# psoc6_04 register map
Vendor: Cypress Semiconductor; Series: PSoC6_04; File version: 1.0
CPU: CM4 r0p1, little endian, MPU, FPU, VTOR, 3 interrupt priority bits
Registers are 32-bit, read-write, reset 0x0 unless marked. A register's access mark holds for its fields unless they carry their own. Offsets are from the block's base; [hi:lo] are bit positions; {n}, {i} and the like mark numbered series; <NAME> marks a mode.

## SAR0 — SAR ADC with Sequencer
Base 0x409B0000
Same registers: SAR1 0x409C0000
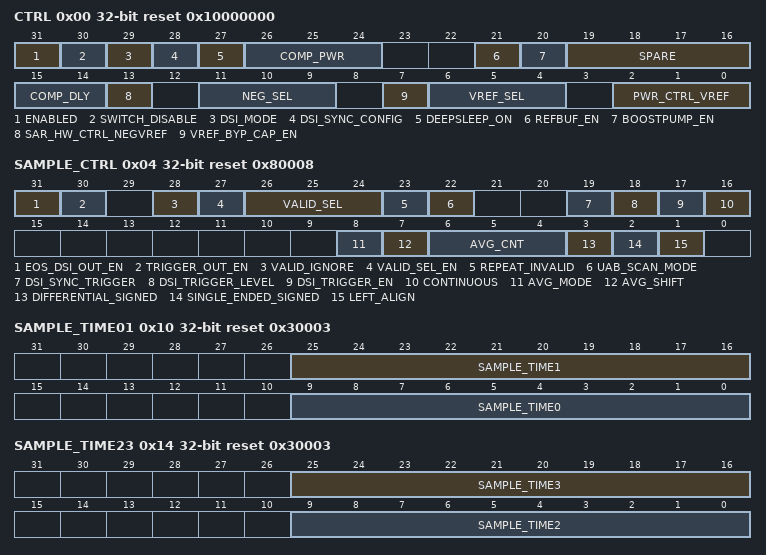
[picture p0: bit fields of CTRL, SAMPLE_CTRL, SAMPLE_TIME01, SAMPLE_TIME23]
0x00 CTRL reset 0x10000000 — Analog control register.
  [31] ENABLED — - 0: SAR IP disabled (put analog in power down and stop clocks), also can clear FW_TRIGGER and INJ_START_EN (if not tailgating) on write. - 1: SAR IP enabled.
  [30] SWITCH_DISABLE — Disable SAR sequencer from enabling routing switches (note DSI and firmware can always close switches independent of this control) - 0: Normal mode, SAR sequencer changes switches according to pin address in channel configurations - 1: Switches disabled, SAR sequencer does not enable any switches, it is the responsibility of the firmware or UDBs (through DSI) to set the switches to route the signal to be converted through the SARMUX
  [29] DSI_MODE — SAR sequencer takes configuration from DSI signals (note this also has the same effect as SWITCH_DISABLE==1) - 0: Normal mode, SAR sequencer operates according to CHAN_EN enables and CHAN_CONFIG channel configurations - 1: CHAN_EN, INJ_START_EN and channel configurations in CHAN_CONFIG and INJ_CHAN_CONFIG are ignored
  [28] DSI_SYNC_CONFIG — - 0: bypass clock domain synchronization of the DSI config signals. - 1: synchronize the DSI config signals to peripheral clock domain.
  [27] DEEPSLEEP_ON — - 0: SARMUX IP disabled off during DeepSleep power mode - 1: SARMUX IP remains enabled during DeepSleep power mode (if ENABLED=1)
  [26:24] COMP_PWR — Comparator power mode. (Sample rate TBD)
    0=P100 (Power = 100 percent, Use this for SAR Clock Frequency greater than 18MHz); 1=P80 (N/A); 2=P60 (Power = 60 percent, Use this for SAR Clock Frequency greater than 1.8MHz up to 18MHz.); 3=P50 (N/A); 4=P40 (N/A); 5=P30 (N/A); 6=P20 (Power = 20 percent, Use this for SAR Clock Frequency less than or equal to 1.8MHz); 7=P10 (N/A)
  [21] REFBUF_EN — For normal ADC operation this bit must be set, for all reference choices - internal, external or vdda based reference. Setting this bit is critical to proper function of switches inside SARREF block.
  [20] BOOSTPUMP_EN — deprecated
  [19:16] SPARE — Spare controls, not yet designated, for late changes done with an ECO
  [15:14] COMP_DLY — Set the comparator latch delay in accordance with SAR conversion rate
    0=D2P5 (2.5ns delay, use this for 2.5Msps); 1=D4 (4.0ns delay, use this for 2.0Msps); 2=D10 (10ns delay, use this for 1.5Msps); 3=D12 (12ns delay, use this for 1.0Msps or less)
  [13] SAR_HW_CTRL_NEGVREF — Hardware control: 0=only firmware control, 1=hardware control masked by firmware setting for VREF to NEG switch.
  [11:9] NEG_SEL — SARADC internal NEG selection for Single ended conversion
    0=VSSA_KELVIN (NEG input of SARADC is connected to 'vssa_kelvin', gives more precision around zero. Note this opens both SARADC internal switches, therefore use this value to insert a break-before-make cycle on those switches when SWITCH_DISABLE is high.); 1=ART_VSSA (NEG input of SARADC is connected to VSSA in AROUTE close to the SARADC); 2=P1 (NEG input of SARADC is connected to P1 pin of SARMUX); 3=P3 (NEG input of SARADC is connected to P3 pin of SARMUX); 4=P5 (NEG input of SARADC is connected to P5 pin of SARMUX); 5=P7 (NEG input of SARADC is connected to P7 pin of SARMUX); 6=ACORE (NEG input of SARADC is connected to an ACORE in AROUTE); 7=VREF (NEG input of SARADC is shorted with VREF input of SARADC.)
  [7] VREF_BYP_CAP_EN — VREF bypass cap enable for when VREF buffer is on
  [6:4] VREF_SEL — SARADC internal VREF selection.
    0=VREF0 (VREF0 from PRB (VREF buffer on)); 1=VREF1 (VREF1 from PRB (VREF buffer on)); 2=VREF2 (VREF2 from PRB (VREF buffer on)); 3=VREF_AROUTE (VREF from AROUTE (VREF buffer on)); 4=VBGR (1.024V from BandGap (VREF buffer on)); 5=VREF_EXT (External precision Vref direct from a pin (low impedance path).); 6=VDDA_DIV_2 (Vdda/2 (VREF buffer on)); 7=VDDA
  [2:0] PWR_CTRL_VREF — VREF buffer low power mode.
    0=PWR_100 (full power (100 percent) (default), bypass cap, max clk_sar is 18MHz.); 1=PWR_80 (80 percent power); 2=PWR_60 (60 percent power); 3=PWR_50 (50 percent power); 4=PWR_40 (40 percent power); 5=PWR_30 (30 percent power); 6=PWR_20 (20 percent power); 7=PWR_10 (10 percent power)
0x04 SAMPLE_CTRL reset 0x80008 — Sample control register.
  [31] EOS_DSI_OUT_EN — Enable to output EOS_INTR to DSI. When enabled each time EOS_INTR is set by the hardware also a trigger pulse is send on the tr_sar_out signal.
  [30] TRIGGER_OUT_EN — SAR output trigger enable (used for UAB synchronization). To ensure multiple UABs starting at the same trigger it is recommended to use this bit to temporarily disable the trigger output until all those UABs are set to run (UAB.SRAM_CTRL.RUN=1).
  [28] VALID_IGNORE — Ignore UAB valid signal, including the dynamic/Hardware from AROUTE and the static Valid selection from the VALID_SEL fields above
  [27] VALID_SEL_EN — Enable static UAB Valid selection (override Hardware)
  [26:24] VALID_SEL — Static UAB Valid select 0=UAB0 half 0 Valid output 1=UAB0 half 1 Valid output 2=UAB1 half 0 Valid output 3=UAB1 half 1 Valid output 4=UAB2 half 0 Valid output 5=UAB2 half 1 Valid output 6=UAB3 half 0 Valid output 7=UAB3 half 1 Valid output
  [23] REPEAT_INVALID — For unscheduled UAB_SCAN_MODE only, do the following if an invalid sample is received: - 0: use the last known valid sample for that channel and clear the NEWVALUE flag - 1: repeat the conversions until a valid sample is received (caveat: could be never if the UAB valid window is incorrectly schedule w.r.t. SAR sampling)
  [22] UAB_SCAN_MODE — Select whether UABs are scheduled or unscheduled. When no UAB is scanned this selection is ignored.
    0=UNSCHEDULED (Unscheduled UABs: one or more of the UABs scanned by the SAR is not scheduled, for each channel that scans a UAB the SAR will wait for a positive edge on the trigger output of that UAB. Caveat: in this mode the length of SAR scan can be variable.); 1=SCHEDULED (Scheduled UABs: All UABs scanned by the SAR are assumed to be properly scheduled, i.e. their output is assumed to be valid when sampled by the SAR and the SAR does not wait. In this mode the length of the SAR scan is constant. This mode requires that the SAR scans strictly periodically, i.e. the SAR has to either run continuously or has to be triggered by a periodic hardware trigger (TCPWM or UDB timer). It also requires that the end of the UAB valid phase is precisely aligned with the end of the SAR sample period (using UAB.STARTUP_DELAY). Normally this scheduling is done by Creator.)
  [19] DSI_SYNC_TRIGGER — - 0: bypass clock domain synchronization of the trigger signal. - 1: synchronize the trigger signal to the SAR clock domain, if needed an edge detect is done in the peripheral clock domain.
  [18] DSI_TRIGGER_LEVEL — - 0: trigger signal is a pulse input, a positive edge detected on the trigger signal triggers a new scan. - 1: trigger signal is a level input, as long as the trigger signal remains high the SAR will do continuous scans. This field cannot be set when SAR_CLOCK_SEL.CLOCK_SEL =1.
  [17] DSI_TRIGGER_EN — - 0: firmware trigger only: disable hardware trigger tr_sar_in. - 1: enable hardware trigger tr_sar_in (e.g. from TCPWM, GPIO or UDB).
  [16] CONTINUOUS — - 0: Wait for next FW_TRIGGER (one shot) or hardware trigger (e.g. from TPWM for periodic triggering) before scanning enabled channels. - 1: Continuously scan enabled channels, ignore triggers. This field cannot be set when SAR_CLOCK_SEL.CLOCK_SEL =1.
  [8] AVG_MODE — Averaging mode, in DSI mode this bit is ignored and only AccuNDump mode is available.
    0=ACCUNDUMP (Accumulate and Dump (1st order accumulate and dump filter): a channel will be sampled back to back and averaged); 1=INTERLEAVED (Interleaved: Each scan (trigger) one sample is taken per channel and averaged over several scans. Interleaved averaging cannot be set by SAR_CLOCK_SEL.CLOCK_SEL =1.)
  [7] AVG_SHIFT — Averaging shifting: after averaging the result is shifted right to fit in 12 bits.
  [6:4] AVG_CNT — Averaging Count for channels that have averaging enabled (AVG_EN). A channel will be sampled (1<<(AVG_CNT+1)) = [2..256] times. - In ACCUNDUMP mode (1st order accumulate and dump filter) a channel will be sampled back to back, the average result is calculated and stored and then the next enabled channel is sampled. If shifting is not enabled (AVG_SHIFT=0) then the result is forced to shift right so that is fits in 16 bits, so right shift is done by max(0,AVG_CNT-3). - In INTERLEAVED mode one sample is taken per triggered scan, only in the scan where the final averaging count is reached a valid average is calculated and stored in the RESULT register (by definition the same scan for all the channels that have averaging enabled). In all other scans the RESULT register for averaged channels will have an invalid result and the intermediate accumulated value is stored in the 16-bit WORK register. In this mode make sure that the averaging count is low enough to ensure that the intermediate value does not exceed 16-bits otherwise the MSBs will be lost. So for a 12-bit resolution the averaging count should be set to 16 or less (AVG_CNT=<3).
  [3] DIFFERENTIAL_SIGNED — Output data from a differential conversion as a signed value when DIFFERENTIAL_EN or NEG_ADDR_EN is set to 1 If AVG_MODE = 1 (Interleaved averaging), then DIFFERENTIAL_SIGNED must be configured identically to SINGLE_ENDED_SIGNED.
    0=UNSIGNED (result data is unsigned (zero extended if needed)); 1=SIGNED (Default: result data is signed (sign extended if needed))
  [2] SINGLE_ENDED_SIGNED — Output data from a single ended conversion as a signed value If AVG_MODE = 1 (Interleaved averaging), then SINGLE_ENDED_SIGNED must be configured identically to DIFFERENTIAL_SIGNED.
    0=UNSIGNED (Default: result data is unsigned (zero extended if needed)); 1=SIGNED (result data is signed (sign extended if needed))
  [1] LEFT_ALIGN — Left align data in data[15:0], default data is right aligned in data[11:0], with sign extension to 16 bits if the channel is differential.
0x10 SAMPLE_TIME01 reset 0x30003 — Sample time specification ST0 and ST1
  [25:16] SAMPLE_TIME1
  [9:0] SAMPLE_TIME0 — Sample time0 (aperture) in ADC clock cycles. Note that actual sample time is one clock less than specified here. The minimum sample time is 167ns, which is 3.0 cycles (4 in this field) with an 18MHz clock. Minimum legal value in this register is 2.
0x14 SAMPLE_TIME23 reset 0x30003 — Sample time specification ST2 and ST3
  [25:16] SAMPLE_TIME3, [9:0] SAMPLE_TIME2
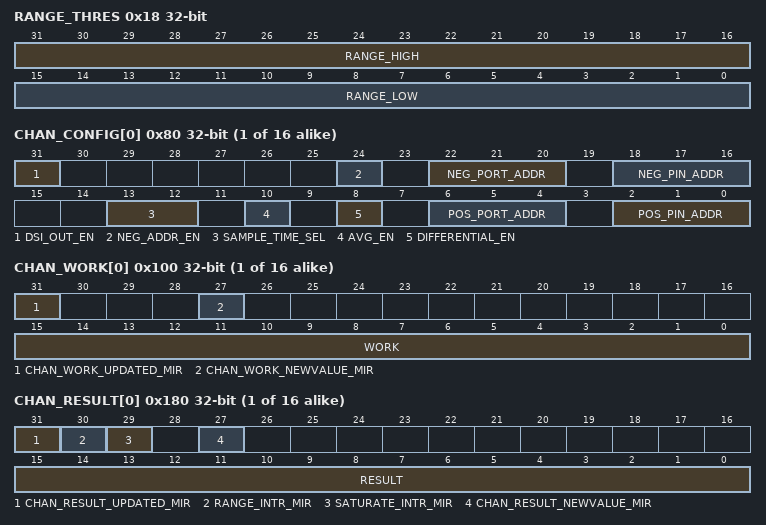
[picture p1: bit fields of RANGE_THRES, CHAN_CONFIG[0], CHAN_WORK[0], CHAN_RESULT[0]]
0x18 RANGE_THRES — Global range detect threshold register.
  [31:16] RANGE_HIGH — High threshold for range detect.
  [15:0] RANGE_LOW — Low threshold for range detect.
0x1C RANGE_COND — Global range detect mode register.
  [31:30] RANGE_COND — Range condition select.
    0=BELOW (result < RANGE_LOW); 1=INSIDE (RANGE_LOW <= result < RANGE_HIGH); 2=ABOVE (RANGE_HIGH <= result); 3=OUTSIDE (result < RANGE_LOW || RANGE_HIGH <= result)
0x20 CHAN_EN — Enable bits for the channels
  [15:0] CHAN_EN — Channel enable. - 0: the corresponding channel is disabled. - 1: the corresponding channel is enabled, it will be included in the next scan.
0x24 START_CTRL — Start control register (firmware trigger).
  [0] FW_TRIGGER — When firmware writes a 1 here it will trigger the next scan of enabled channels, hardware clears this bit when the scan started with this trigger is completed. If scanning continuously the trigger is ignored and hardware clears this bit after the next scan is done. This bit is also cleared when the SAR is disabled. This fiel+G201d cannot be set when SAR_CLOCK_SEL.CLOCK_SEL =1.
{0x80+4i} CHAN_CONFIG[{i}] (i=0..15) — Channel configuration register.
  [31] DSI_OUT_EN — DSI data output enable for this channel. - 0: the conversion result for this channel is only stored in the channel data register and the corresponding CHAN_DATA_VALID bit is set. - 1: the conversion result for this channel is stored in the channel data register and the corresponding CHAN_DATA_VALID bit is set. The same data (same formatting), together with the channel number, is sent out on the DSI communication channel for processing in UDBs.
  [24] NEG_ADDR_EN — 1 - The NEG_PIN_ADDR and NEG_PORT_ADDR determines what drives the Vminus pin. This is a variation of differential mode with no even-odd pair limitation 0 - The NEG_SEL determines what drives the Vminus pin.
  [22:20] NEG_PORT_ADDR — Address of the neg port that contains the pin to be sampled by this channel.
    0=SARMUX (SARMUX pins.); 5=AROUTE_VIRT2 (AROUTE virtual port2 (VPORT2)); 6=AROUTE_VIRT1 (AROUTE virtual port1 (VPORT1)); 7=SARMUX_VIRT (SARMUX virtual port (VPORT0))
  [18:16] NEG_PIN_ADDR — Address of the neg pin to be sampled by this channel.
  [13:12] SAMPLE_TIME_SEL — Sample time select: select which of the 4 global sample times to use for this channel
  [10] AVG_EN — Averaging enable for this channel. If set the AVG_CNT and AVG_SHIFT settings are used for sampling the addressed pin(s)
  [8] DIFFERENTIAL_EN — Differential enable for this channel. If NEG_ADDR_EN=0 and this bit is 1 then POS_PIN_ADDR[0] is ignored and considered to be 0, i.e. POS_PIN_ADDR points to the even pin of a pin pair. In that case the even pin of the pair is connected to Vplus and the odd pin of the pair is connected to Vminus. POS_PORT_ADDR is used to identify the port that contains the pins. - 0: The voltage on the addressed pin is measured (Single-ended) and the resulting value is stored in the corresponding data register. - 1: The differential voltage on the addressed pin pair is measured and the resulting value is stored in the corresponding data register. (if NEG_ADDR_EN=0 then POS_PIN_ADDR[0] is ignored).
  [6:4] POS_PORT_ADDR — Address of the port that contains the pin to be sampled by this channel (connected to Vplus)
    0=SARMUX (SARMUX pins.); {v}=CTB{v-1} (v=1..4); 5=AROUTE_VIRT2 (AROUTE virtual port2 (VPORT2)); 6=AROUTE_VIRT1 (AROUTE virtual port1 (VPORT1)); 7=SARMUX_VIRT (SARMUX virtual port (VPORT0))
  [2:0] POS_PIN_ADDR — Address of the pin to be sampled by this channel (connected to Vplus)
{0x100+4i} CHAN_WORK[{i}] (i=0..15) ro (reset mask 0x88000000) — Channel working data register
  [31] CHAN_WORK_UPDATED_MIR — mirror bit of corresponding bit in SAR_CHAN_WORK_UPDATED register. This field cannot be read if SAR_CLOCK_SEL.CLOCK_SEL =1.
  [27] CHAN_WORK_NEWVALUE_MIR — mirror bit of corresponding bit in SAR_CHAN_WORK_NEWVALUE register. This field cannot be read if SAR_CLOCK_SEL.CLOCK_SEL =1.
  [15:0] WORK — SAR conversion working data of the channel. The data is written here right after sampling this channel. This field cannot be read if SAR_CLOCK_SEL.CLOCK_SEL =1.
{0x180+4i} CHAN_RESULT[{i}] (i=0..15) ro (reset mask 0xE8000000) — Channel result data register
  [31] CHAN_RESULT_UPDATED_MIR — mirror bit of corresponding bit in SAR_CHAN_RESULT_UPDATED register. This field cannot be read if SAR_CLOCK_SEL.CLOCK_SEL =1.
  [30] RANGE_INTR_MIR — mirror bit of corresponding bit in SAR_RANGE_INTR register. This field cannot be read if SAR_CLOCK_SEL.CLOCK_SEL =1.
  [29] SATURATE_INTR_MIR — mirror bit of corresponding bit in SAR_SATURATE_INTR register. This field cannot be read if SAR_CLOCK_SEL.CLOCK_SEL =1.
  [27] CHAN_RESULT_NEWVALUE_MIR — mirror bit of corresponding bit in SAR_CHAN_RESULT_NEWVALUE register. This field cannot be read if SAR_CLOCK_SEL.CLOCK_SEL =1.
  [15:0] RESULT — SAR conversion result of the channel. The data is copied here from the WORK field after all enabled channels in this scan have been sampled. This field cannot be read if SAR_CLOCK_SEL.CLOCK_SEL =1.
0x200 CHAN_WORK_UPDATED ro — Channel working data register 'updated' bits
  [15:0] CHAN_WORK_UPDATED — If set the corresponding WORK register was updated, i.e. was already sampled during the current scan and, in case of Interleaved averaging, reached the averaging count. If this bit is low then either the channel is not enabled or the averaging count is not yet reached for Interleaved averaging. This field cannot be read if SAR_CLOCK_SEL.CLOCK_SEL =1.
0x204 CHAN_RESULT_UPDATED ro — Channel result data register 'updated' bits
  [15:0] CHAN_RESULT_UPDATED — If set the corresponding RESULT register was updated, i.e. was sampled during the previous scan and, in case of Interleaved averaging, reached the averaging count. If this bit is low then either the channel is not enabled or the averaging count is not yet reached for Interleaved averaging. This field cannot be read if SAR_CLOCK_SEL.CLOCK_SEL =1.
0x208 CHAN_WORK_NEWVALUE ro — Channel working data register 'new value' bits
  [15:0] CHAN_WORK_NEWVALUE — If set the corresponding WORK data received a new value, i.e. was already sampled during the current scan and data was valid. In case of a UAB this New Value bit reflects the value of UAB.valid output, for anything else the data is always valid. In case of averaging this New Value bit is an OR of all the valid bits received by each conversion. This field cannot be read if SAR_CLOCK_SEL.CLOCK_SEL =1.
0x20C CHAN_RESULT_NEWVALUE ro — Channel result data register 'new value' bits
  [15:0] CHAN_RESULT_NEWVALUE — If set the corresponding RESULT data received a new value, i.e. was sampled during the last scan and data was valid. In case of a UAB this New Value bit reflects the value of UAB.valid output, for anything else the data is always valid. In case of averaging this New Value bit is an OR of all the valid bits received by each conversion. This field cannot be read if SAR_CLOCK_SEL.CLOCK_SEL =1.
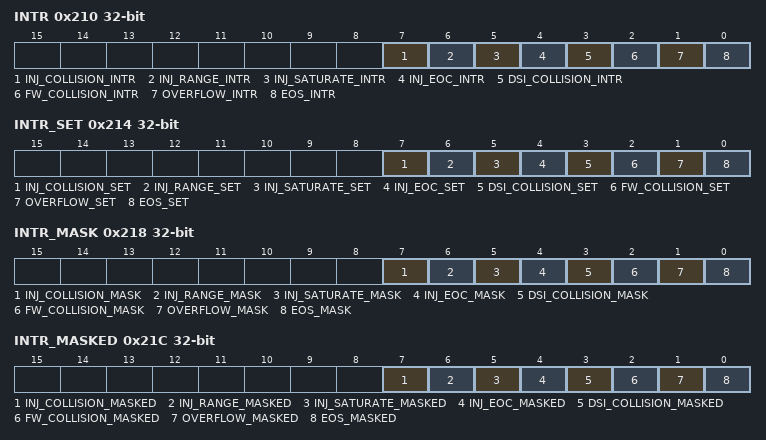
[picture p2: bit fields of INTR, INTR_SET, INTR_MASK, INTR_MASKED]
0x210 INTR — Interrupt request register.
  [7] INJ_COLLISION_INTR — Injection Collision Interrupt: hardware sets this interrupt when the injection trigger signal is asserted (INJ_START_EN==1 && INJ_TAILGATING==0) while the SAR is BUSY. Raising this interrupt is delayed to when the sampling of the injection channel has been completed, i.e. not when the preceding scan with which this trigger collided is completed. When this interrupt is set it implies that the injection channel was sampled later than was intended. Write with '1' to clear bit. This interrupt cannot be used if SAR_CLOCK_SEL.CLOCK_SEL =1.
  [6] INJ_RANGE_INTR — Injection Range detect Interrupt: hardware sets this interrupt if the injection conversion result (after averaging) met the condition specified by the SAR_RANGE registers. Write with '1' to clear bit. This interrupt cannot be used if SAR_CLOCK_SEL.CLOCK_SEL =1.
  [5] INJ_SATURATE_INTR — Injection Saturation Interrupt: hardware sets this interrupt if an injection conversion result (before averaging) is either 0x000 or 0xFFF, this is an indication that the ADC likely saturated. Write with '1' to clear bit. This interrupt cannot be used if SAR_CLOCK_SEL.CLOCK_SEL =1.
  [4] INJ_EOC_INTR — Injection End of Conversion Interrupt: hardware sets this interrupt after completing the conversion for the injection channel (irrespective of if tailgating was used). Write with '1' to clear bit. This interrupt cannot be used if SAR_CLOCK_SEL.CLOCK_SEL =1.
  [3] DSI_COLLISION_INTR — DSI Collision Interrupt: hardware sets this interrupt when the DSI trigger signal is asserted while the SAR is BUSY. Raising this interrupt is delayed to when the scan caused by the DSI trigger has been completed, i.e. not when the preceding scan with which this trigger collided is completed. When this interrupt is set it implies that the channels were sampled later than was intended (jitter). Write with '1' to clear bit. This interrupt cannot be used if SAR_CLOCK_SEL.CLOCK_SEL =1.
  [2] FW_COLLISION_INTR — Firmware Collision Interrupt: hardware sets this interrupt when FW_TRIGGER is asserted while the SAR is BUSY. Raising this interrupt is delayed to when the scan caused by the FW_TRIGGER has been completed, i.e. not when the preceding scan with which this trigger collided is completed. When this interrupt is set it implies that the channels were sampled later than was intended (jitter). Write with '1' to clear bit. This interrupt cannot be used if SAR_CLOCK_SEL.CLOCK_SEL =1.
  [1] OVERFLOW_INTR — Overflow Interrupt: hardware sets this interrupt when it sets a new EOS_INTR while that bit was not yet cleared by the firmware. Write with '1' to clear bit. This interrupt cannot be used if SAR_CLOCK_SEL.CLOCK_SEL =1.
  [0] EOS_INTR — End Of Scan Interrupt: hardware sets this interrupt after completing a scan of all the enabled channels. Write with '1' to clear bit.
0x214 INTR_SET — Interrupt set request register
  [7] INJ_COLLISION_SET — Write with '1' to set corresponding bit in interrupt request register.
  [6] INJ_RANGE_SET — Write with '1' to set corresponding bit in interrupt request register.
  [5] INJ_SATURATE_SET — Write with '1' to set corresponding bit in interrupt request register.
  [4] INJ_EOC_SET — Write with '1' to set corresponding bit in interrupt request register.
  [3] DSI_COLLISION_SET — Write with '1' to set corresponding bit in interrupt request register.
  [2] FW_COLLISION_SET — Write with '1' to set corresponding bit in interrupt request register.
  [1] OVERFLOW_SET — Write with '1' to set corresponding bit in interrupt request register.
  [0] EOS_SET — Write with '1' to set corresponding bit in interrupt request register.
0x218 INTR_MASK — Interrupt mask register.
  [7] INJ_COLLISION_MASK — Mask bit for corresponding bit in interrupt request register.
  [6] INJ_RANGE_MASK — Mask bit for corresponding bit in interrupt request register.
  [5] INJ_SATURATE_MASK — Mask bit for corresponding bit in interrupt request register.
  [4] INJ_EOC_MASK — Mask bit for corresponding bit in interrupt request register.
  [3] DSI_COLLISION_MASK — Mask bit for corresponding bit in interrupt request register.
  [2] FW_COLLISION_MASK — Mask bit for corresponding bit in interrupt request register.
  [1] OVERFLOW_MASK — Mask bit for corresponding bit in interrupt request register.
  [0] EOS_MASK — Mask bit for corresponding bit in interrupt request register.
0x21C INTR_MASKED ro — Interrupt masked request register
  [7] INJ_COLLISION_MASKED — Logical and of corresponding request and mask bits.
  [6] INJ_RANGE_MASKED — Logical and of corresponding request and mask bits.
  [5] INJ_SATURATE_MASKED — Logical and of corresponding request and mask bits.
  [4] INJ_EOC_MASKED — Logical and of corresponding request and mask bits.
  [3] DSI_COLLISION_MASKED — Logical and of corresponding request and mask bits.
  [2] FW_COLLISION_MASKED — Logical and of corresponding request and mask bits.
  [1] OVERFLOW_MASKED — Logical and of corresponding request and mask bits.
  [0] EOS_MASKED — Logical and of corresponding request and mask bits.
0x220 SATURATE_INTR — Saturate interrupt request register.
  [15:0] SATURATE_INTR — Saturate Interrupt: hardware sets this interrupt for each channel if a conversion result (before averaging) of that channel is either 0x000 or 0xFFF, this is an indication that the ADC likely saturated. Write with '1' to clear bit.
0x224 SATURATE_INTR_SET — Saturate interrupt set request register
  [15:0] SATURATE_SET — Write with '1' to set corresponding bit in interrupt request register.
0x228 SATURATE_INTR_MASK — Saturate interrupt mask register.
  [15:0] SATURATE_MASK — Mask bit for corresponding bit in interrupt request register.
0x22C SATURATE_INTR_MASKED ro — Saturate interrupt masked request register
  [15:0] SATURATE_MASKED — Logical and of corresponding request and mask bits.
0x230 RANGE_INTR — Range detect interrupt request register.
  [15:0] RANGE_INTR — Range detect Interrupt: hardware sets this interrupt for each channel if the conversion result (after averaging) of that channel met the condition specified by the SAR_RANGE registers. Write with '1' to clear bit.
0x234 RANGE_INTR_SET — Range detect interrupt set request register
  [15:0] RANGE_SET — Write with '1' to set corresponding bit in interrupt request register.
0x238 RANGE_INTR_MASK — Range detect interrupt mask register.
  [15:0] RANGE_MASK — Mask bit for corresponding bit in interrupt request register.
0x23C RANGE_INTR_MASKED ro — Range interrupt masked request register
  [15:0] RANGE_MASKED — Logical and of corresponding request and mask bits.
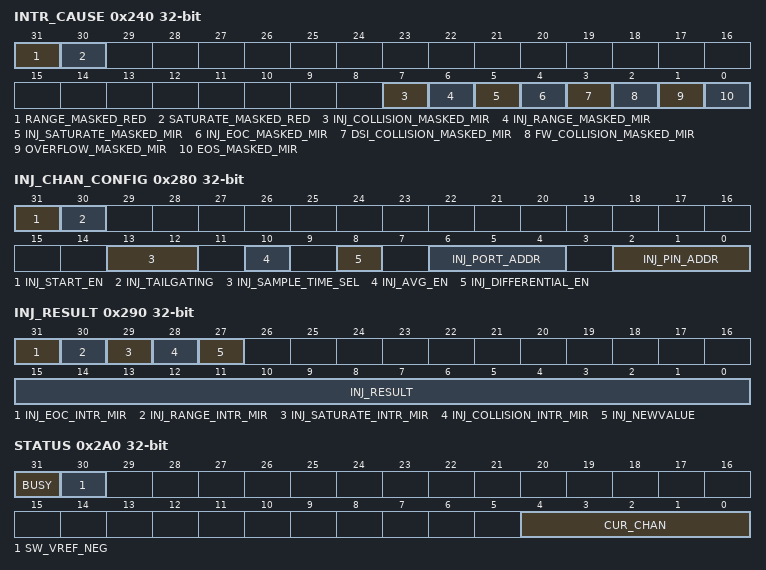
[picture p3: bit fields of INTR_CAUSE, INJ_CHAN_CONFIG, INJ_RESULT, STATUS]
0x240 INTR_CAUSE ro — Interrupt cause register
  [31] RANGE_MASKED_RED — Reduction OR of all SAR_RANGE_INTR_MASKED bits
  [30] SATURATE_MASKED_RED — Reduction OR of all SAR_SATURATION_INTR_MASKED bits
  [7] INJ_COLLISION_MASKED_MIR — Mirror copy of corresponding bit in SAR_INTR_MASKED
  [6] INJ_RANGE_MASKED_MIR — Mirror copy of corresponding bit in SAR_INTR_MASKED
  [5] INJ_SATURATE_MASKED_MIR — Mirror copy of corresponding bit in SAR_INTR_MASKED
  [4] INJ_EOC_MASKED_MIR — Mirror copy of corresponding bit in SAR_INTR_MASKED
  [3] DSI_COLLISION_MASKED_MIR — Mirror copy of corresponding bit in SAR_INTR_MASKED
  [2] FW_COLLISION_MASKED_MIR — Mirror copy of corresponding bit in SAR_INTR_MASKED
  [1] OVERFLOW_MASKED_MIR — Mirror copy of corresponding bit in SAR_INTR_MASKED
  [0] EOS_MASKED_MIR — Mirror copy of corresponding bit in SAR_INTR_MASKED
0x280 INJ_CHAN_CONFIG — Injection channel configuration register.
  [31] INJ_START_EN — Set by firmware to enable the injection channel. If INJ_TAILGATING is not set this bit also functions as trigger for this channel. Cleared by hardware after this channel has been sampled (i.e. this channel is always one shot even if CONTINUOUS is set). Also cleared if the SAR is disabled. This field cannot be set when SAR_CLOCK_SEL.CLOCK_SEL =1.
  [30] INJ_TAILGATING — Injection channel tailgating. - 0: no tailgating for this channel, SAR is immediately triggered when the INJ_START_EN bit is set if the SAR is not busy. If the SAR is busy, the INJ channel addressed pin is sampled at the end of the current scan. - 1: injection channel tailgating. The addressed pin is sampled after the next trigger and after all enabled channels have been scanned.
  [13:12] INJ_SAMPLE_TIME_SEL — Injection sample time select: select which of the 4 global sample times to use for this channel
  [10] INJ_AVG_EN — Averaging enable for this channel. If set the AVG_CNT and AVG_SHIFT settings are used for sampling the addressed pin(s)
  [8] INJ_DIFFERENTIAL_EN — Differential enable for this channel. - 0: The voltage on the addressed pin is measured (Single-ended) and the resulting value is stored in the corresponding data register. - 1: The differential voltage on the addressed pin pair is measured and the resulting value is stored in the corresponding data register. (INJ_PIN_ADDR[0] is ignored).
  [6:4] INJ_PORT_ADDR — Address of the port that contains the pin to be sampled by this channel.
    0=SARMUX (SARMUX pins.); {v}=CTB{v-1} (v=1..4); 6=AROUTE_VIRT (AROUTE virtual port); 7=SARMUX_VIRT (SARMUX virtual port)
  [2:0] INJ_PIN_ADDR — Address of the pin to be sampled by this injection channel. If differential is enabled then INJ_PIN_ADDR[0] is ignored and considered to be 0, i.e. INJ_PIN_ADDR points to the even pin of a pin pair.
0x290 INJ_RESULT ro (reset mask 0xF8000000) — Injection channel result register
  [31] INJ_EOC_INTR_MIR — mirror bit of corresponding bit in SAR_INTR register. This field cannot be read if SAR_CLOCK_SEL.CLOCK_SEL =1.
  [30] INJ_RANGE_INTR_MIR — mirror bit of corresponding bit in SAR_INTR register. This field cannot be read if SAR_CLOCK_SEL.CLOCK_SEL =1.
  [29] INJ_SATURATE_INTR_MIR — mirror bit of corresponding bit in SAR_INTR register. This field cannot be read if SAR_CLOCK_SEL.CLOCK_SEL =1.
  [28] INJ_COLLISION_INTR_MIR — mirror bit of corresponding bit in SAR_INTR register. This field cannot be read if SAR_CLOCK_SEL.CLOCK_SEL =1.
  [27] INJ_NEWVALUE — The data in this register received a new value (only relevant for UAB, this bit shows the value of the UAB valid bit). This field cannot be read if SAR_CLOCK_SEL.CLOCK_SEL =1.
  [15:0] INJ_RESULT — SAR conversion result of the channel. This field cannot be read if SAR_CLOCK_SEL.CLOCK_SEL =1.
0x2A0 STATUS ro — Current status of internal SAR registers (mostly for debug)
  [31] BUSY — If high then the SAR is busy with a conversion. This bit is always high when CONTINUOUS is set. Firmware should wait for this bit to be low before putting the SAR in power down.
  [30] SW_VREF_NEG — the current switch status, including DSI and sequencer controls, of the switch in the SARADC that shorts NEG with VREF input (see NEG_SEL). This field cannot be read if SAR_CLOCK_SEL.CLOCK_SEL =1.
  [4:0] CUR_CHAN — current channel being sampled (channel 16 indicates the injection channel), only valid if BUSY. This field cannot be read if SAR_CLOCK_SEL.CLOCK_SEL =1.
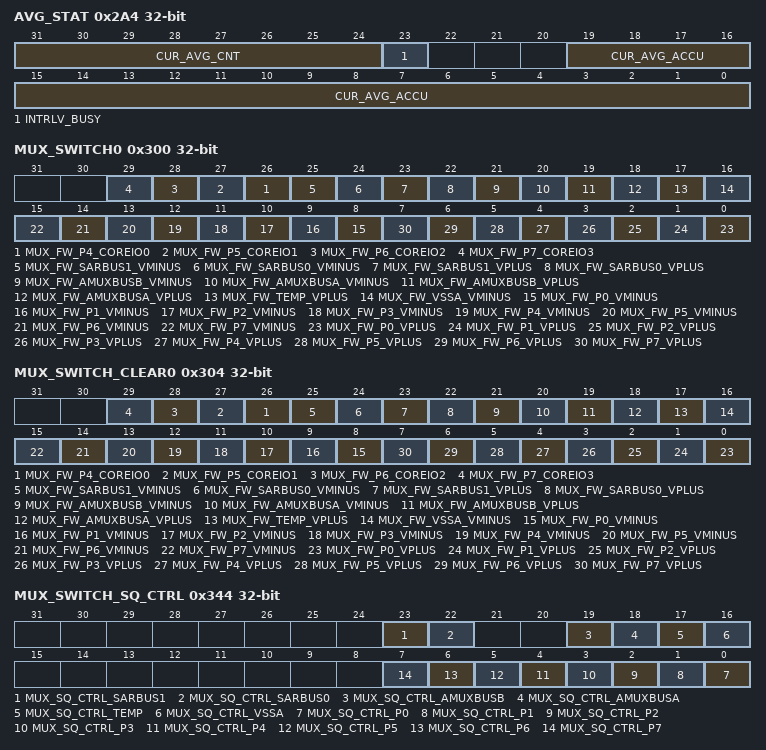
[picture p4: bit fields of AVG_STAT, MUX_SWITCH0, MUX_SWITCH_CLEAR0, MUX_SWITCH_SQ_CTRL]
0x2A4 AVG_STAT ro — Current averaging status (for debug)
  [31:24] CUR_AVG_CNT — the current value of the averaging counter. Note that the value shown is updated after the sampling time and therefore runs ahead of the accumulator update. This field cannot be read if SAR_CLOCK_SEL.CLOCK_SEL =1.
  [23] INTRLV_BUSY — If high then the SAR is in the middle of Interleaved averaging spanning several scans. While this bit is high the Firmware should not make any changes to the configuration registers otherwise some results may be incorrect. Note that the CUR_AVG_CNT status register below gives an indication how many more scans need to be done to complete the Interleaved averaging. This bit can be cleared by changing the averaging mode to ACCUNDUMP or by disabling the SAR.
  [19:0] CUR_AVG_ACCU — the current value of the averaging accumulator. This field cannot be read if SAR_CLOCK_SEL.CLOCK_SEL =1.
0x300 MUX_SWITCH0 — SARMUX Firmware switch controls
  [n+22] MUX_FW_P{n}_COREIO{n-4} (n=4..7) — Firmware control: 0=open, 1=close switch between P{n} and coreio{n-4} signal. Write with '1' to set bit.
  [25] MUX_FW_SARBUS1_VMINUS — Firmware control: 0=open, 1=close switch between sarbus1 and vminus signal. Write with '1' to set bit.
  [24] MUX_FW_SARBUS0_VMINUS — Firmware control: 0=open, 1=close switch between sarbus0 and vminus signal. Write with '1' to set bit.
  [23] MUX_FW_SARBUS1_VPLUS — Firmware control: 0=open, 1=close switch between sarbus1 and vplus signal. Write with '1' to set bit.
  [22] MUX_FW_SARBUS0_VPLUS — Firmware control: 0=open, 1=close switch between sarbus0 and vplus signal. Write with '1' to set bit.
  [21] MUX_FW_AMUXBUSB_VMINUS — Firmware control: 0=open, 1=close switch between amuxbusb and vminus signal. Write with '1' to set bit.
  [20] MUX_FW_AMUXBUSA_VMINUS — Firmware control: 0=open, 1=close switch between amuxbusa and vminus signal. Write with '1' to set bit.
  [19] MUX_FW_AMUXBUSB_VPLUS — Firmware control: 0=open, 1=close switch between amuxbusb and vplus signal. Write with '1' to set bit.
  [18] MUX_FW_AMUXBUSA_VPLUS — Firmware control: 0=open, 1=close switch between amuxbusa and vplus signal. Write with '1' to set bit.
  [17] MUX_FW_TEMP_VPLUS — Firmware control: 0=open, 1=close switch between temperature sensor and vplus signal, (also powers on the temperature sensor if AREF_CTRL.EN=1 (active mode) and AREF_CTRL.DEEPSLEEP=1 and AREF_CTRL.DEEPSLEEP_MODE=2 or 3 (required for deepsleep mode only). The Write with '1' to set bit.
  [16] MUX_FW_VSSA_VMINUS — Firmware control: 0=open, 1=close switch between vssa_kelvin and vminus signal. Write with '1' to set bit.
  [n+8] MUX_FW_P{n}_VMINUS (n=0..7) — Firmware control: 0=open, 1=close switch between pin P{n} and vminus signal. Write with '1' to set bit.
  [n] MUX_FW_P{n}_VPLUS (n=0..7) — Firmware control: 0=open, 1=close switch between pin P{n} and vplus signal. Write with '1' to set bit.
0x304 MUX_SWITCH_CLEAR0 — SARMUX Firmware switch control clear
  [n+22] MUX_FW_P{n}_COREIO{n-4} (n=4..7) — Write '1' to clear corresponding bit in MUX_SWITCH0
  [25] MUX_FW_SARBUS1_VMINUS — Write '1' to clear corresponding bit in MUX_SWITCH0
  [24] MUX_FW_SARBUS0_VMINUS — Write '1' to clear corresponding bit in MUX_SWITCH0
  [23] MUX_FW_SARBUS1_VPLUS — Write '1' to clear corresponding bit in MUX_SWITCH0
  [22] MUX_FW_SARBUS0_VPLUS — Write '1' to clear corresponding bit in MUX_SWITCH0
  [21] MUX_FW_AMUXBUSB_VMINUS — Write '1' to clear corresponding bit in MUX_SWITCH0
  [20] MUX_FW_AMUXBUSA_VMINUS — Write '1' to clear corresponding bit in MUX_SWITCH0
  [19] MUX_FW_AMUXBUSB_VPLUS — Write '1' to clear corresponding bit in MUX_SWITCH0
  [18] MUX_FW_AMUXBUSA_VPLUS — Write '1' to clear corresponding bit in MUX_SWITCH0
  [17] MUX_FW_TEMP_VPLUS — Write '1' to clear corresponding bit in MUX_SWITCH0
  [16] MUX_FW_VSSA_VMINUS — Write '1' to clear corresponding bit in MUX_SWITCH0
  [n+8] MUX_FW_P{n}_VMINUS (n=0..7) — Write '1' to clear corresponding bit in MUX_SWITCH0
  [n] MUX_FW_P{n}_VPLUS (n=0..7) — Write '1' to clear corresponding bit in MUX_SWITCH0
0x344 MUX_SWITCH_SQ_CTRL — SARMUX switch Sar Sequencer control
  [23] MUX_SQ_CTRL_SARBUS1 — for sarbus1 switch
  [22] MUX_SQ_CTRL_SARBUS0 — for sarbus0 switch
  [19] MUX_SQ_CTRL_AMUXBUSB — for amuxbusb switches
  [18] MUX_SQ_CTRL_AMUXBUSA — for amuxbusa switch
  [17] MUX_SQ_CTRL_TEMP — for temp switch
  [16] MUX_SQ_CTRL_VSSA — for vssa switch
  [n] MUX_SQ_CTRL_P{n} (n=0..7) — for P{n} switches
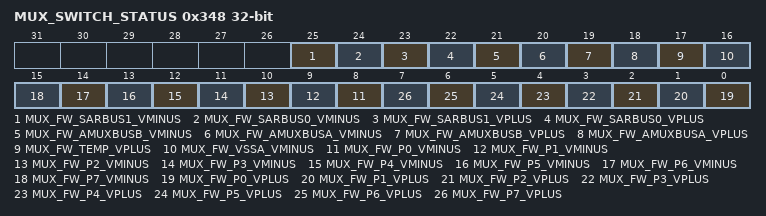
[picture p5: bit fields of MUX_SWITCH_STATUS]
0x348 MUX_SWITCH_STATUS ro — SARMUX switch status
  [25] MUX_FW_SARBUS1_VMINUS — switch status of corresponding bit in MUX_SWITCH0. This field cannot be read if SAR_CLOCK_SEL.CLOCK_SEL =1.
  [24] MUX_FW_SARBUS0_VMINUS — switch status of corresponding bit in MUX_SWITCH0. This field cannot be read if SAR_CLOCK_SEL.CLOCK_SEL =1.
  [23] MUX_FW_SARBUS1_VPLUS — switch status of corresponding bit in MUX_SWITCH0. This field cannot be read if SAR_CLOCK_SEL.CLOCK_SEL =1.
  [22] MUX_FW_SARBUS0_VPLUS — switch status of corresponding bit in MUX_SWITCH0. This field cannot be read if SAR_CLOCK_SEL.CLOCK_SEL =1.
  [21] MUX_FW_AMUXBUSB_VMINUS — switch status of corresponding bit in MUX_SWITCH0. This field cannot be read if SAR_CLOCK_SEL.CLOCK_SEL =1.
  [20] MUX_FW_AMUXBUSA_VMINUS — switch status of corresponding bit in MUX_SWITCH0. This field cannot be read if SAR_CLOCK_SEL.CLOCK_SEL =1.
  [19] MUX_FW_AMUXBUSB_VPLUS — switch status of corresponding bit in MUX_SWITCH0. This field cannot be read if SAR_CLOCK_SEL.CLOCK_SEL =1.
  [18] MUX_FW_AMUXBUSA_VPLUS — switch status of corresponding bit in MUX_SWITCH0. This field cannot be read if SAR_CLOCK_SEL.CLOCK_SEL =1.
  [17] MUX_FW_TEMP_VPLUS — switch status of corresponding bit in MUX_SWITCH0. This field cannot be read if SAR_CLOCK_SEL.CLOCK_SEL =1.
  [16] MUX_FW_VSSA_VMINUS — switch status of corresponding bit in MUX_SWITCH0. This field cannot be read if SAR_CLOCK_SEL.CLOCK_SEL =1.
  [n+8] MUX_FW_P{n}_VMINUS (n=0..7) — switch status of corresponding bit in MUX_SWITCH0. This field cannot be read if SAR_CLOCK_SEL.CLOCK_SEL =1.
  [n] MUX_FW_P{n}_VPLUS (n=0..7) — switch status of corresponding bit in MUX_SWITCH0. This field cannot be read if SAR_CLOCK_SEL.CLOCK_SEL =1.
